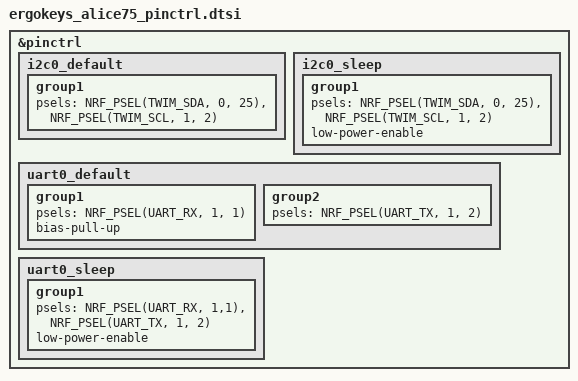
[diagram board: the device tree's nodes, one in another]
&pinctrl {
    i2c0_default: i2c0_default {
        group1 {
            psels = <NRF_PSEL(TWIM_SDA, 0, 25)>,
                <NRF_PSEL(TWIM_SCL, 1, 2)>;
        };
    };

    i2c0_sleep: i2c0_sleep {
        group1 {
            psels = <NRF_PSEL(TWIM_SDA, 0, 25)>,
                <NRF_PSEL(TWIM_SCL, 1, 2)>;
            low-power-enable;
        };
    };

    uart0_default: uart0_default {
        group1 {
            psels = <NRF_PSEL(UART_RX, 1, 1)>;
            bias-pull-up;
        };
        group2 {
            psels = <NRF_PSEL(UART_TX, 1, 2)>;
        };
    };

    uart0_sleep: uart0_sleep {
        group1 {
            psels = <NRF_PSEL(UART_RX, 1,1)>,
                <NRF_PSEL(UART_TX, 1, 2)>;
            low-power-enable;
        };
    };
};
